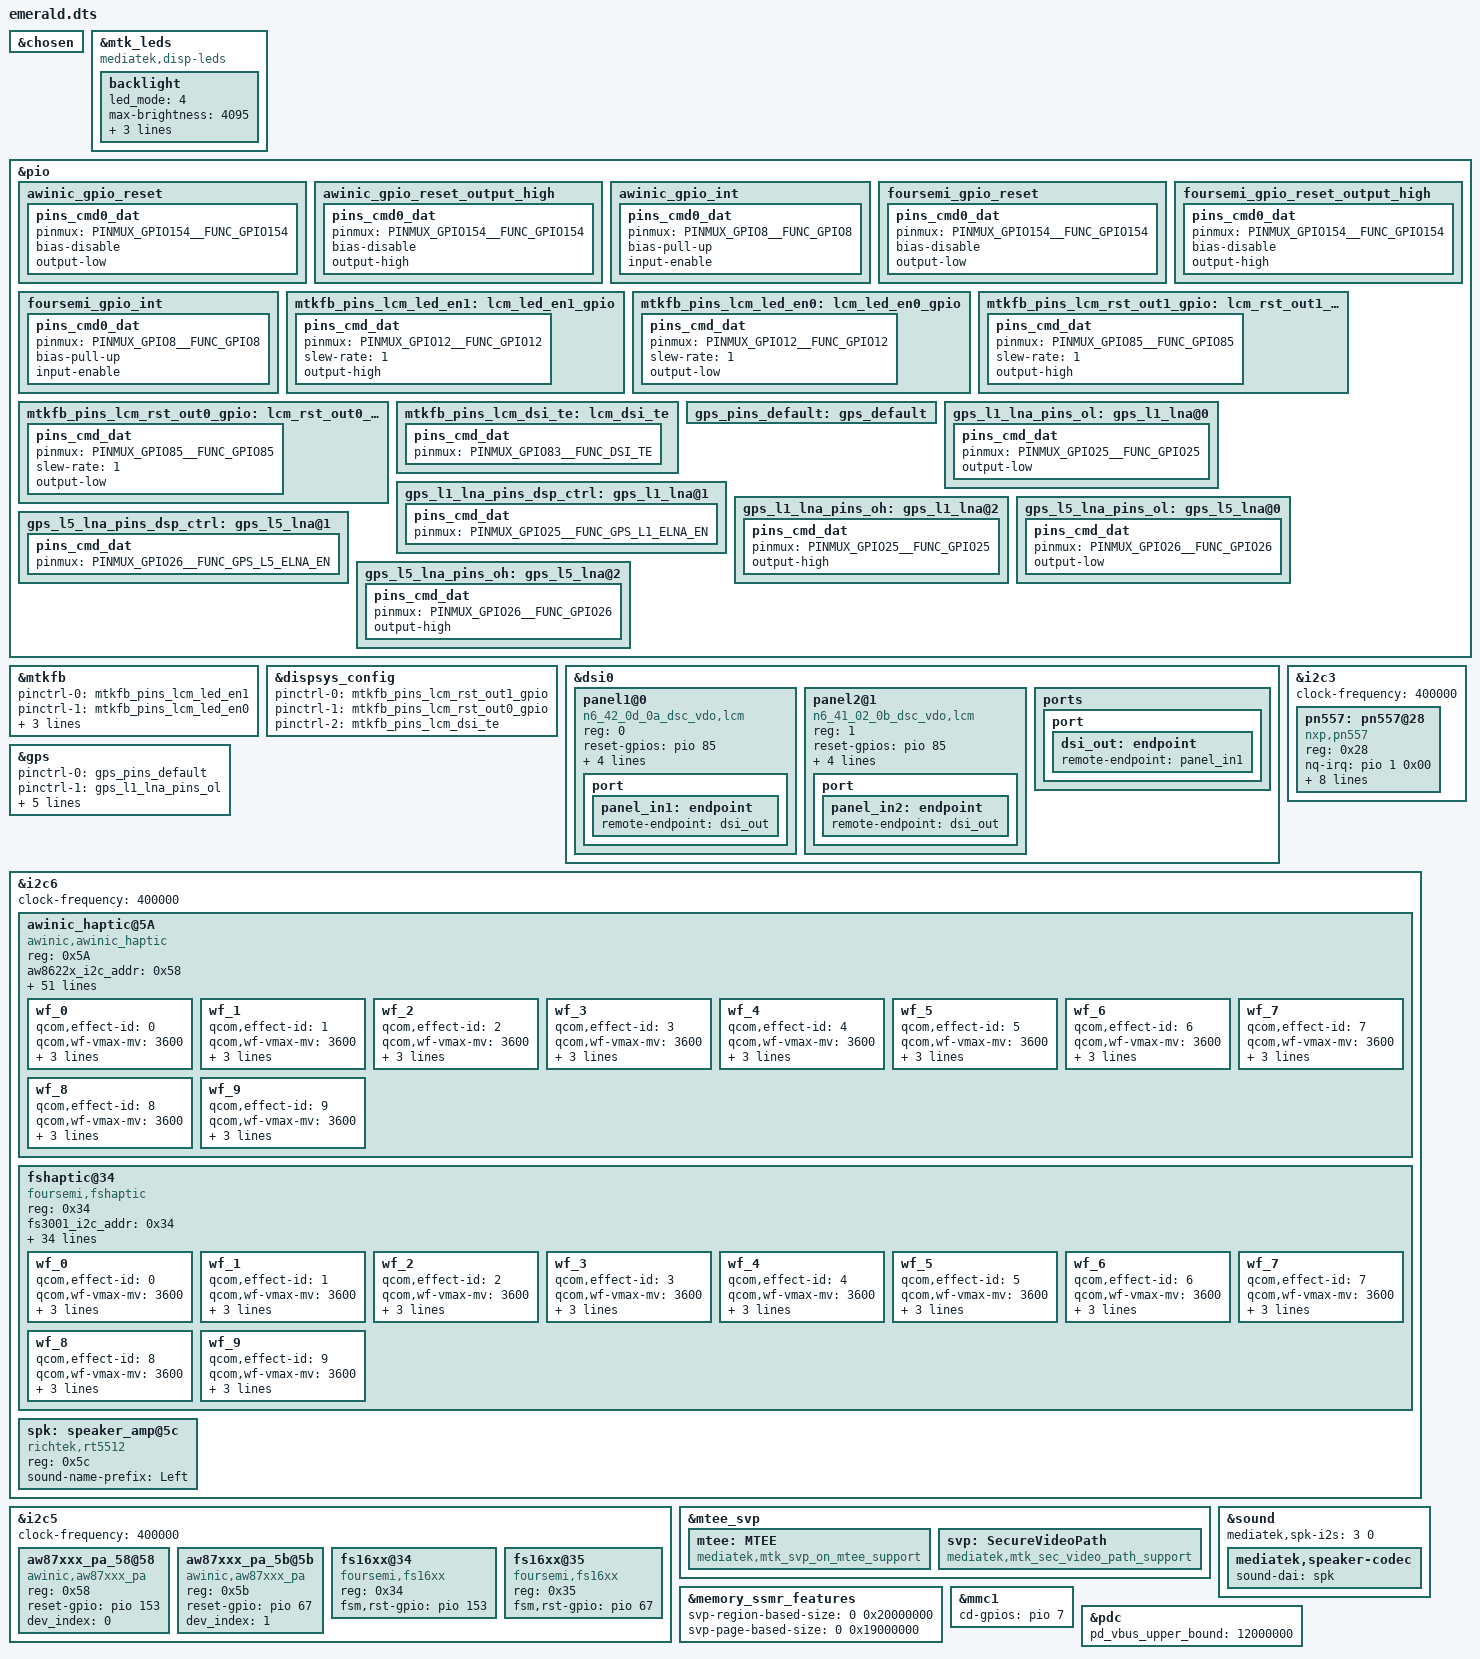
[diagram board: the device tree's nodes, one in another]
// SPDX-License-Identifier: (GPL-2.0 OR MIT)
/*
 * Copyright (C) 2021 MediaTek Inc.
 */
/dts-v1/;
/plugin/;
#include <dt-bindings/interrupt-controller/arm-gic.h>
#include <dt-bindings/interrupt-controller/irq.h>
#include <dt-bindings/pinctrl/mt6789-pinfunc.h>
/* N6 code for HQ-309545 by huabinchen at 2023/07/05 start */
#include "mediatek/cust_mt6789_camera_n6.dtsi"
/* N6 code for HQ-309545 by huabinchen at 2023/07/05 end */
/* N6 code for HQ-301667 by wanghan at 20230628 start */
#include <dt-bindings/gpio/gpio.h>
/* N6 code for HQ-301667 by wanghan at 20230628 start */

/* N6 code for HQ-301669 by wumingzhu1 at 20230705 */
#include "mediatek/hq_chg/hq_chg.dtsi"

&chosen {

};

/*N6 code for HQ-301708 by zhengjie at 2023/7/5 start*/
/*N6 code for HQ-302375 by zhengjie at 2023/7/12 start*/
&mtk_leds {
	compatible = "mediatek,disp-leds";

	backlight {
		led_mode = <4>;
		max-brightness = <4095>;
		max-hw-brightness = <4095>;
		//gate_enable = <1>;
		data = <1>;
		pwm_config = <12 12>;
	};
};
/*N6 code for HQ-302375 by zhengjie at 2023/7/12 end*/
/*N6 code for HQ-301708 by zhengjie at 2023/7/5 end*/

&pio {
 /* N6 code for HQ-301698 by p-dongfeiju at 2023/07/10 start */
	/* AW86224_RESET_N */
	awinic_gpio_reset: awinic_gpio_reset {
		pins_cmd0_dat {
			pinmux = <PINMUX_GPIO154__FUNC_GPIO154>;
			bias-disable;
			output-low;
		};
	};
	/* AW8624_RESET_N, state device active*/
	awinic_gpio_reset_output_high: awinic_gpio_reset_output_high {
		pins_cmd0_dat {
			pinmux = <PINMUX_GPIO154__FUNC_GPIO154>;
			bias-disable;
			output-high;
		};
	};
	/* AW86224_INTERRUPT_N */
	awinic_gpio_int: awinic_gpio_int {
		pins_cmd0_dat {
			pinmux = <PINMUX_GPIO8__FUNC_GPIO8>;
			bias-pull-up;
			input-enable;
		};
	};

		/* foursemi_RESET_N */
	foursemi_gpio_reset: foursemi_gpio_reset {
		pins_cmd0_dat {
			pinmux = <PINMUX_GPIO154__FUNC_GPIO154>;
			bias-disable;
			output-low;
		};
	};
	/* foursemi_RESET_N, state device active*/
	foursemi_gpio_reset_output_high: foursemi_gpio_reset_output_high {
		pins_cmd0_dat {
			pinmux = <PINMUX_GPIO154__FUNC_GPIO154>;
			bias-disable;
			output-high;
		};
	};
	/* foursemi_INTERRUPT_N */
	foursemi_gpio_int: foursemi_gpio_int {
		pins_cmd0_dat {
			pinmux = <PINMUX_GPIO8__FUNC_GPIO8>;
			bias-pull-up;
			input-enable;
		};
	};

 /* N6 code for HQ-301698 by p-dongfeiju at 2023/07/10 end */
	mtkfb_pins_lcm_led_en1: lcm_led_en1_gpio {
		pins_cmd_dat {
			pinmux = <PINMUX_GPIO12__FUNC_GPIO12>;
			slew-rate = <1>;
			output-high;
		};
	};

	mtkfb_pins_lcm_led_en0: lcm_led_en0_gpio {
		pins_cmd_dat {
			pinmux = <PINMUX_GPIO12__FUNC_GPIO12>;
			slew-rate = <1>;
			output-low;
		};
	};

	mtkfb_pins_lcm_rst_out1_gpio: lcm_rst_out1_gpio {
		pins_cmd_dat {
			pinmux = <PINMUX_GPIO85__FUNC_GPIO85>;
			slew-rate = <1>;
			output-high;
		};
	};

	mtkfb_pins_lcm_rst_out0_gpio: lcm_rst_out0_gpio {
		pins_cmd_dat {
			pinmux = <PINMUX_GPIO85__FUNC_GPIO85>;
			slew-rate = <1>;
			output-low;
		};
	};
	mtkfb_pins_lcm_dsi_te: lcm_dsi_te {
		pins_cmd_dat {
			pinmux = <PINMUX_GPIO83__FUNC_DSI_TE>;
		};
	};
};

&mtkfb {
	pinctrl-names = "lcm_led_en1_gpio", "lcm_led_en0_gpio",
		"lcm_rst_out1_gpio", "lcm_rst_out0_gpio",
		"mode_te_te";
	pinctrl-0 = <&mtkfb_pins_lcm_led_en1>;
	pinctrl-1 = <&mtkfb_pins_lcm_led_en0>;
	pinctrl-2 = <&mtkfb_pins_lcm_rst_out1_gpio>;
	pinctrl-3 = <&mtkfb_pins_lcm_rst_out0_gpio>;
	pinctrl-4 = <&mtkfb_pins_lcm_dsi_te>;
	status = "okay";
};

&dispsys_config {
	pinctrl-names =
		"lcm_rst_out1_gpio", "lcm_rst_out0_gpio",
		"mode_te_te";
	pinctrl-0 = <&mtkfb_pins_lcm_rst_out1_gpio>;
	pinctrl-1 = <&mtkfb_pins_lcm_rst_out0_gpio>;
	pinctrl-2 = <&mtkfb_pins_lcm_dsi_te>;
	status = "okay";
};

/*N6 code for HQ-301708 by zhengjie at 2023/7/5 start*/
&dsi0 {
	status = "okay";
	#address-cells = <1>;
	#size-cells = <0>;
	panel1@0 {
		compatible = "n6_42_0d_0a_dsc_vdo,lcm";
		reg = <0>;
		//pm-enable-gpios = <&pio 12 0>;
		reset-gpios = <&pio 85 0>;
		vddi-gpios = <&pio 156 0>;
		vdd-gpios = <&pio 14 0>;
		vci-gpios = <&pio 155 0>;
		mi,esd-err-irq-gpio = <&pio 5 0>;
		//gate-ic = <4831>;
		pinctrl-names = "default";
		port {
			panel_in1: endpoint {
				remote-endpoint = <&dsi_out>;
			};
		};
	};
/*N6 code for HQ-305068 by zhengjie at 2023/9/19 start*/
/*N6 code for HQ-339295 by zhengjie at 2023/10/20 start*/
	panel2@1 {
		compatible = "n6_41_02_0b_dsc_vdo,lcm";
		reg = <1>;
		//pm-enable-gpios = <&pio 12 0>;
		reset-gpios = <&pio 85 0>;
		vddi-gpios = <&pio 156 0>;
		vdd-gpios = <&pio 14 0>;
		vci-gpios = <&pio 155 0>;
		mi,esd-err-irq-gpio = <&pio 5 0>;
		//gate-ic = <4831>;
		pinctrl-names = "default";
		port {
			panel_in2: endpoint {
				remote-endpoint = <&dsi_out>;
			};
		};
	};
/*N6 code for HQ-339295 by zhengjie at 2023/10/20 end*/
/*N6 code for HQ-305068 by zhengjie at 2023/9/19 end*/
	ports {
		port {
			dsi_out: endpoint {
				remote-endpoint = <&panel_in1>;
			};
		};
	};
};
/*N6 code for HQ-301708 by zhengjie at 2023/7/5 end*/

/* GPS GPIO standardization start */
&pio {
	gps_pins_default: gps_default {
	};
	gps_l1_lna_pins_ol: gps_l1_lna@0 {
		pins_cmd_dat {
			pinmux = <PINMUX_GPIO25__FUNC_GPIO25>;
			output-low;
		};
	};
	gps_l1_lna_pins_dsp_ctrl: gps_l1_lna@1 {
		pins_cmd_dat {
			pinmux = <PINMUX_GPIO25__FUNC_GPS_L1_ELNA_EN>;
		};
	};
	gps_l1_lna_pins_oh: gps_l1_lna@2 {
		pins_cmd_dat {
			pinmux = <PINMUX_GPIO25__FUNC_GPIO25>;
			output-high;
		};
	};
	gps_l5_lna_pins_ol: gps_l5_lna@0 {
		pins_cmd_dat {
			pinmux = <PINMUX_GPIO26__FUNC_GPIO26>;
			output-low;
		};
	};
	gps_l5_lna_pins_dsp_ctrl: gps_l5_lna@1 {
		pins_cmd_dat {
			pinmux = <PINMUX_GPIO26__FUNC_GPS_L5_ELNA_EN>;
		};
	};
	gps_l5_lna_pins_oh: gps_l5_lna@2 {
		pins_cmd_dat {
			pinmux = <PINMUX_GPIO26__FUNC_GPIO26>;
			output-high;
		};
	};
};
&gps {
	pinctrl-names = "default",
		"gps_l1_lna_disable",
		"gps_l1_lna_dsp_ctrl",
		"gps_l1_lna_enable",
		"gps_l5_lna_disable",
		"gps_l5_lna_dsp_ctrl",
		"gps_l5_lna_enable";
	pinctrl-0 = <&gps_pins_default>;
	pinctrl-1 = <&gps_l1_lna_pins_ol>;
	pinctrl-2 = <&gps_l1_lna_pins_dsp_ctrl>;
	pinctrl-3 = <&gps_l1_lna_pins_oh>;
	pinctrl-4 = <&gps_l5_lna_pins_ol>;
	pinctrl-5 = <&gps_l5_lna_pins_dsp_ctrl>;
	pinctrl-6 = <&gps_l5_lna_pins_oh>;
	status = "okay";
};
/* GPS GPIO standardization end */

/* N17 code for HQ-290883 by zhangyize at 2023.4.19 start */
/* N17 code for HQ-290883 by zhangyize at 2023.4.19 start */

&i2c3 {
        status = "ok";
        clock-frequency = <400000>;
        pn557: pn557@28 {
                compatible = "nxp,pn557";
                reg = <0x28>;
                nq-irq = <&pio 1 0x00>;
                interrupt-parent = <&pio>;
                interrupts = <1 IRQ_TYPE_LEVEL_HIGH 1 0>;
                nq-ven = <&pio 100 0x0>;
                nq-firm = <&pio 108 0x0>;
                nq-clkreq = <&pio 68 0x0>;
                interrupt-names = "irq_nfc";
//add TMS NFC
                tms,irq-gpio        = <&pio 1 0x00>;
                tms,ven-gpio        = <&pio 100 0x0>;
                tms,download-gpio   = <&pio 108 0x0>;
                status = "okay";
        };
};

/* N6 code for HQ-301702 by liaoxianguo at 2023/7/5 start */
/* #include "mediatek/cust_mt6789_touch_1080x2400.dtsi" */
#include "mediatek/emerald_mt6789_touch_1080x2400.dtsi"
/* N6 code for HQ-301702 by liaoxianguo at 2023/7/5 end */
#include "mediatek/cust_mt6789_camera_v4l2.dtsi"
 /* N6 code for HQ-301698 by p-dongfeiju at 2023/07/10 start */
/* N6 code for HQ-301685 by p-yaochuxue at 2023/07/21 start */
#include "mediatek/cust_mt6789_fingerprint.dtsi"
/* N6 code for HQ-301685 by p-yaochuxue at 2023/07/21 end */
&i2c6 {
	status = "ok";
	clock-frequency = <400000>;
	awinic_haptic@5A {
		compatible = "awinic,awinic_haptic";
		reg = <0x5A>;
		aw8622x_i2c_addr = < 0x58 >;
		reset-gpio = <&pio 154 0>;
		irq-gpio = <&pio 8 0>;
		pinctrl-names = "awinic_reset_reset","awinic_reset_active","awinic_interrupt_active";
		pinctrl-0 = <&awinic_gpio_reset>;
		pinctrl-1 = <&awinic_gpio_reset_output_high>;
		pinctrl-2 = <&awinic_gpio_int>;
		/*---------------------aw8624_dts_info---------------------*/
		aw8624_vib_f0_pre = < 2080 >;
		aw8624_vib_f0_cali_percen = < 7 >;
		aw8624_vib_cont_drv_lev = < 106 >;
		aw8624_vib_cont_drv_lvl_ov = < 155 >;
		aw8624_vib_cont_td = < 0xF06C >;
		aw8624_vib_cont_zc_thr = < 0x08F8 >;
		aw8624_vib_cont_num_brk = < 3 >;
		aw8624_vib_f0_coeff = < 260 >; /*Don't modify it*/
		aw8624_vib_duration_time = < 15 60 0 0 0 >;
		aw8624_vib_brake_ram_config = < 1 1 90 60 20 3 1 3 1 1 90 60 30 5 1 3 0 0 50 40 25 0 5 3 >;
		aw8624_vib_brake_cont_config = < 1 1 90 42 20 5 2 2 0 0 0 0 0 0 0 0 0 0 0 0 0 0 0 0 >;
		aw8624_vib_f0_trace_parameter = < 9 5 1 15 >;
		aw8624_vib_bemf_config = < 0 8 3 0xf8 >;
		aw8624_vib_sw_brake = < 0x2c >;
		aw8624_vib_wavseq = < 0 1 1 2 0 0 0 0 0 0 0 0 0 0 0 0 >; /*wavseq1-seq8 0x07-0x0E*/
		aw8624_vib_wavloop = < 0 6 1 15 0 0 0 0 0 0>;/*loop1-mainloog 0x0f-0x13*/
		aw8624_vib_td_brake = < 42720 42720 42720 >; /*level0 level1 level2*/
		aw8624_vib_tset = < 0x11 >;
		aw8624_vib_func_parameter1 = < 1 >;
		aw8624_vib_gain_flag = < 1 >;
		aw8624_vib_r_spare = < 0x68 >;
		aw8624_vib_bstdbg = < 0x30 0xeb 0xd4 0 0 0 >;
		/*---------------------aw8622x_dts_info---------------------*/
		aw8622x_vib_mode = < 0 >; /* mode: RAM mode->0; CONT mode->1 */
		aw8622x_vib_f0_pre = < 2080 >;
		aw8622x_vib_f0_cali_percen = < 7 >;
		aw8622x_vib_cont_drv1_lvl = < 0x7F >;
		aw8622x_vib_cont_drv2_lvl = < 0x36 >;
		aw8622x_vib_cont_brk_time = < 0x06 >;
		aw8622x_vib_cont_tset = < 0x06 >;
		aw8622x_vib_cont_bemf_set = < 0x02 >;
		aw8622x_vib_cont_drv_width = < 0x6A >;
		aw8622x_vib_cont_wait_num = < 0x06 >;
		aw8622x_vib_cont_brk_gain = < 0x08 >;
		aw8622x_vib_cont_drv1_time = < 0x04 >;
		aw8622x_vib_cont_drv2_time = < 0x14 >;
		aw8622x_vib_cont_track_margin = < 0x12 >;
		aw8622x_vib_sine_array = < 0x05 0xB2 0xFF 0xEF >; /* SIN_H SIN_L COS_H COS_L*/
		aw8622x_vib_d2s_gain = < 0x05 >;
		aw8622x_vib_prctmode = < 0x2D 0x3E 0x3F >;
		/*---------------------common_dts_info---------------------*/
		vib_effect_id_boundary = < 10 >;
		vib_effect_max = < 193 >;
		vib_rtp_time = < 20 20 20 20 40 20 20 20 20 20
				 20 20 20 20 20 20 20 20 20 20
				 20 24058 11520 14770 40341 22060 16745 15166 10590 17260
				 16923 16000 9920 14420 12000 18000 7860 19400 12600 31992
				 18581 30093 39836 19500 8530 9692 2000 16820 18782 14223
				 1034 1161 2096 874 1606 795 1788 859 1260 1668
				 2254 1852 5126 1931 1204 890 1803 1822 1325 2607
				 1015 890 208 676 679 850 357 380 1140 457
				 1176 1400 328 1500 100 150 100 341 100 249
				 704 100 1000 479 100 1 1089 1 2103 23181
				 1 620 100 466 178 1 100 785 124 140
				 414 97 39 462 165 152 295 1 64 4088
				 965 931 308 3584 4583 4289 100 70 1 1656
				 89 56 76 56 51 681 1 36 1 1
				 83 129 216 87 128 215 227 534 312 90
				 299 1109 686 395 10500 5648 6708 618 749 701
				 814 2610 200 200 300 200 200 300 200 200
				 300 516 286 200 200 200 400 1200 200 400
				 200 200 350 200 400 250 300 200 250 200
				 300 600 23200 1 1 1 1 1 1 1 >;
		status = "okay";
		wf_0 {
			//CLICK
			qcom,effect-id = <0>;
			qcom,wf-vmax-mv = <3600>;
			qcom,wf-pattern = [3e 3e];
			qcom,wf-brake-pattern = [02 01 00 00];
			qcom,wf-play-rate-us = <20000>;
		};
		wf_1 {
			//DOUBLE CLICK
			qcom,effect-id = <1>;
			qcom,wf-vmax-mv = <3600>;
			qcom,wf-pattern = [7e 3e];
			qcom,wf-brake-pattern = [03 01 00 00];
			qcom,wf-play-rate-us = <20000>;
		};
		wf_2 {
			//TICK
			qcom,effect-id = <2>;
			qcom,wf-vmax-mv = <3600>;
			qcom,wf-pattern = [7e 3e];
			qcom,wf-brake-pattern = [02 01 00 00];
			qcom,wf-play-rate-us = <20000>;
		};
		wf_3 {
			//THUD
			qcom,effect-id = <3>;
			qcom,wf-vmax-mv = <3600>;
			qcom,wf-pattern = [3e 3e];
			qcom,wf-brake-pattern = [02 01 00 00];
			qcom,wf-play-rate-us = <20000>;
		};
		wf_4 {
			//POP
			qcom,effect-id = <4>;
			qcom,wf-vmax-mv = <3600>;
			qcom,wf-pattern = [3e 3e];
			qcom,wf-brake-pattern = [02 01 00 00];
			qcom,wf-play-rate-us = <28000>;
		};
		wf_5 {
			//HEAVY CLICK
			qcom,effect-id = <5>;
			qcom,wf-vmax-mv = <3600>;
			qcom,wf-pattern = [7e 7e 7e];
			qcom,wf-brake-pattern = [03 03 01 00];
			qcom,wf-play-rate-us = <20000>;
		};
		wf_6 {
			//id 6
			qcom,effect-id = <6>;
			qcom,wf-vmax-mv = <3600>;
			qcom,wf-pattern = [3e 3e];
			qcom,wf-brake-pattern = [02 01 00 00];
			qcom,wf-play-rate-us = <20000>;
		};
		wf_7 {
			//id 7
			qcom,effect-id = <7>;
			qcom,wf-vmax-mv = <3600>;
			qcom,wf-pattern = [3e 3e];
			qcom,wf-brake-pattern = [02 01 00 00];
			qcom,wf-play-rate-us = <20000>;
		};
		wf_8 {
			//id 8
			qcom,effect-id = <8>;
			qcom,wf-vmax-mv = <3600>;
			qcom,wf-pattern = [3e 3e];
			qcom,wf-brake-pattern = [02 01 00 00];
			qcom,wf-play-rate-us = <20000>;
		};
		wf_9 {
			//id 9
			qcom,effect-id = <9>;
			qcom,wf-vmax-mv = <3600>;
			qcom,wf-pattern = [3e 3e];
			qcom,wf-brake-pattern = [02 01 00 00];
			qcom,wf-play-rate-us = <20000>;
		};
    };
 /* N6 code for HQ-301698 by p-dongfeiju at 2023/07/10 end */
	fshaptic@34 {
		compatible="foursemi,fshaptic";
		reg=<0x34>;
		fs3001_i2c_addr=<0x34>;
		reset-gpio=<&pio 154 0>;
		irq-gpio=<&pio 8 0>;
		pinctrl-names = "foursemi_reset_reset","foursemi_reset_active","foursemi_interrupt_active";
		pinctrl-0 = <&foursemi_gpio_reset>;
		pinctrl-1 = <&foursemi_gpio_reset_output_high>;
		pinctrl-2 = <&foursemi_gpio_int>;
		fs3001_f0_ref=< 2080 >;
		fs3001_f0_cali_mode=< 1 >;
		fs3001_auto_brake=< 0 >;
		fs3001_cont_drv1_lvl=< 127 >;
		fs3001_cont_drv2_lvl=< 54 >;
		fs3001_cont_drv1_time=< 4 >;
		fs3001_cont_drv2_time=< 20 >;
		fs3001_cont_1_period=< 692 >;
		fs3001_brk_slopeth=< 10 >;
		fs3001_brk_gain=< 128 >;
		fs3001_brk_times=< 20 >;
		fs3001_brk_noise_gate=< 16 >;
		fs3001_brk_1_period=< 461 >;
		fs3001_brk_pgagain=< 5 >;
		fs3001_brk_margin=< 48 >;
		fs3001_play_ram_srate=< 0 >;
		fs3001_play_rtp_srate=< 1 >;
		fs3001_default_vib_mode=< 3 >;
		fs3001_vbat_mode=< 0 >;
		fs3001_lk_f0_cali=< 0 >;
/* N6 code for HQ-324229 by p-gaobowei at 2023/09/04 start */
		fs3001_bypass_system_gain=< 0 >;
/* N6 code for HQ-324229 by p-gaobowei at 2023/09/04 end */
		fs3001_f0_cali_data_mode=< 0 >;
		fs3001_lr_pgagain=< 5 >;
		fs3001_rtp_id_boundary = < 10 >;
		fs3001_rtp_max = < 193 >;
		fs3001_rtp_time = < 20 20 20 20 40 20 20 20 20 20
					 20 20 20 20 20 20 20 20 20 20
					 20 24058 11520 14770 40341 22060 16745 15166 10590 17260
					 16923 16000 9920 14420 12000 18000 7860 19400 12600 31992
					 18581 30093 39836 19500 8530 9692 2000 16820 18782 14223
					 1034 1161 2096 874 1606 795 1788 859 1260 1668
					 2254 1852 5126 1931 1204 890 1803 1822 1325 2607
					 1015 890 208 676 679 850 357 380 1140 457
					 1176 1400 328 1500 100 150 100 341 100 249
					 704 100 1000 479 100 1 1089 1 2103 23181
					 1 620 100 466 178 1 100 785 124 140
					 414 97 39 462 165 152 295 1 64 4088
					 965 931 308 3584 4583 4289 100 70 1 1656
					 89 56 76 56 51 681 1 36 1 1
					 83 129 216 87 128 215 227 534 312 90
					 299 1109 686 395 10500 5648 6708 618 749 701
					 814 2610 200 200 300 200 200 300 200 200
					 300 516 286 200 200 200 400 1200 200 400
					 200 200 350 200 400 250 300 200 250 200
					 300 600 23200 1 1 1 1 1 1 1 >;
		fs3001_reg_inits=< 0xffffff 0xffffff 0xffffff 0xffffff 0xffffff 0xffffff 0xffffff 0xffffff 0xffffff 0xffffff >;
		status = "okay";
		wf_0 {
			//CLICK
			qcom,effect-id = <0>;
			qcom,wf-vmax-mv = <3600>;
			qcom,wf-pattern = [3e 3e];
			qcom,wf-brake-pattern = [02 01 00 00];
			qcom,wf-play-rate-us = <20000>;
		};
		wf_1 {
			//DOUBLE CLICK
			qcom,effect-id = <1>;
			qcom,wf-vmax-mv = <3600>;
			qcom,wf-pattern = [7e 3e];
			qcom,wf-brake-pattern = [03 01 00 00];
			qcom,wf-play-rate-us = <20000>;
		};
		wf_2 {
			//TICK
			qcom,effect-id = <2>;
			qcom,wf-vmax-mv = <3600>;
			qcom,wf-pattern = [7e 3e];
			qcom,wf-brake-pattern = [02 01 00 00];
			qcom,wf-play-rate-us = <20000>;
		};
		wf_3 {
			//THUD
			qcom,effect-id = <3>;
			qcom,wf-vmax-mv = <3600>;
			qcom,wf-pattern = [3e 3e];
			qcom,wf-brake-pattern = [02 01 00 00];
			qcom,wf-play-rate-us = <20000>;
		};
		wf_4 {
			//POP
			qcom,effect-id = <4>;
			qcom,wf-vmax-mv = <3600>;
			qcom,wf-pattern = [3e 3e];
			qcom,wf-brake-pattern = [02 01 00 00];
			qcom,wf-play-rate-us = <28000>;
		};
		wf_5 {
			//HEAVY CLICK
			qcom,effect-id = <5>;
			qcom,wf-vmax-mv = <3600>;
			qcom,wf-pattern = [7e 7e 7e];
			qcom,wf-brake-pattern = [03 03 01 00];
			qcom,wf-play-rate-us = <20000>;
		};
		wf_6 {
			//id 6
			qcom,effect-id = <6>;
			qcom,wf-vmax-mv = <3600>;
			qcom,wf-pattern = [3e 3e];
			qcom,wf-brake-pattern = [02 01 00 00];
			qcom,wf-play-rate-us = <20000>;
		};
		wf_7 {
			//id 7
			qcom,effect-id = <7>;
			qcom,wf-vmax-mv = <3600>;
			qcom,wf-pattern = [3e 3e];
			qcom,wf-brake-pattern = [02 01 00 00];
			qcom,wf-play-rate-us = <20000>;
		};
		wf_8 {
			//id 8
			qcom,effect-id = <8>;
			qcom,wf-vmax-mv = <3600>;
			qcom,wf-pattern = [3e 3e];
			qcom,wf-brake-pattern = [02 01 00 00];
			qcom,wf-play-rate-us = <20000>;
		};
		wf_9 {
			//id 9
			qcom,effect-id = <9>;
			qcom,wf-vmax-mv = <3600>;
			qcom,wf-pattern = [3e 3e];
			qcom,wf-brake-pattern = [02 01 00 00];
			qcom,wf-play-rate-us = <20000>;
		};
	};
	spk: speaker_amp@5c {
		compatible = "richtek,rt5512";
		#sound-dai-cells = <0>;
		reg = <0x5c>;
		status = "okay";
		sound-name-prefix = "Left";
	};
};

/* Audio bringup pa dts config zhangguangshuai 20230627 start */
&i2c5 {
	clock-frequency = <400000>;

	aw87xxx_pa_58@58 {
		compatible = "awinic,aw87xxx_pa";
		reg = <0x58>;
		reset-gpio = <&pio 153 0>;
		dev_index = < 0 >;
		status = "okay";
	};
	aw87xxx_pa_5b@5b {
		compatible = "awinic,aw87xxx_pa";
		reg = <0x5b>;
		reset-gpio = <&pio 67 0>;
		dev_index = < 1 >;
		status = "okay";
	};
	fs16xx@34 {
		compatible = "foursemi,fs16xx";
		reg = <0x34>;
		fsm,rst-gpio = <&pio 153 0>;
		status = "okay";
	};
	fs16xx@35 {
		compatible = "foursemi,fs16xx";
		reg = <0x35>;
		fsm,rst-gpio = <&pio 67 0>;
		status = "okay";
	};
};
/* Audio bringup pa dts config zhangguangshuai 20230627 end */

/* N6 code for widevine by zhouyuxuan at 2023/08/18 start*/
&mtee_svp {
	mtee: MTEE {
		compatible = "mediatek,mtk_svp_on_mtee_support";
	};

	svp: SecureVideoPath {
		compatible = "mediatek,mtk_sec_video_path_support";
	};
};

&memory_ssmr_features {
	svp-region-based-size = <0 0x20000000>;
	svp-page-based-size = <0 0x19000000>;
};
/* N6 code for widevine by zhouyuxuan at 2023/08/18 end*/

&sound {
	mediatek,spk-i2s = <3 0>;
	mediatek,speaker-codec {
		sound-dai = <&spk>;
	};
};

/* N6 code for HQ-301667 by wanghan at 20230628 start */
&mmc1 {
	cd-gpios = <&pio 7 GPIO_ACTIVE_HIGH>;
};
/* N6 code for HQ-301667 by wanghan at 20230628 end */

&pdc {
	pd_vbus_upper_bound = <12000000>;
};

#include <emerald/cust.dtsi>
/*End of this file, DO NOT ADD ANYTHING HERE*/
